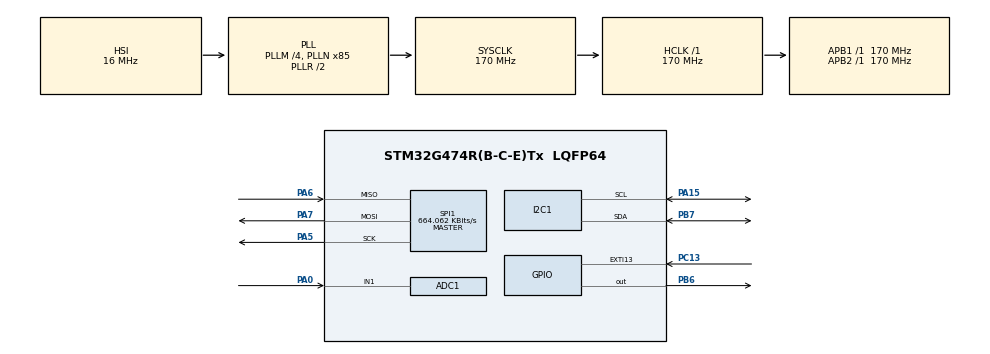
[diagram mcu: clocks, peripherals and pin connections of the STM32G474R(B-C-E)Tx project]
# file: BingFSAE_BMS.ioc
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ADC1.Channel-1\#ChannelRegularConversion=ADC_CHANNEL_1
ADC1.NbrOfConversionFlag=1
ADC1.OffsetNumber-1\#ChannelRegularConversion=ADC_OFFSET_NONE
ADC1.Rank-1\#ChannelRegularConversion=1
ADC1.SamplingTime-1\#ChannelRegularConversion=ADC_SAMPLETIME_2CYCLES_5
ADC1.master=1
I2C1.Timing=0x40B285C2
Mcu.Family=STM32G4
Mcu.Name=STM32G474R(B-C-E)Tx
Mcu.Package=LQFP64
NUCLEO-G474RE.BUTTON=1
NUCLEO-G474RE.LD2=true
NUCLEO-G474RE.VCP=true
NVIC.EXTI15_10_IRQn=true\:0\:0\:false\:false\:true\:true\:true\:true
NVIC.PriorityGroup=NVIC_PRIORITYGROUP_4
PA0.Mode=IN1-Single-Ended
PA0.Signal=ADC1_IN1
PA13.GPIO_Label=T_SWDIO
PA13.Signal=SYS_JTMS-SWDIO
PA14.GPIO_Label=T_SWCLK
PA14.Signal=SYS_JTCK-SWCLK
PA15.Mode=I2C
PA15.Signal=I2C1_SCL
PA2.Signal=LPUART1_TX
PA3.Signal=LPUART1_RX
PA5.Mode=Full_Duplex_Master
PA5.Signal=SPI1_SCK
PA6.Mode=Full_Duplex_Master
PA6.Signal=SPI1_MISO
PA7.Mode=Full_Duplex_Master
PA7.Signal=SPI1_MOSI
PB3.GPIO_Label=T_SWO
PB3.Signal=SYS_JTDO-SWO
PB6.Signal=GPIO_Output
PB7.Mode=I2C
PB7.Signal=I2C1_SDA
PC13.Signal=GPXTI13
PC14-OSC32_IN.GPIO_Label=RCC_OSC32_IN
PC14-OSC32_IN.Signal=RCC_OSC32_IN
PC15-OSC32_OUT.GPIO_Label=RCC_OSC32_OUT
PC15-OSC32_OUT.Signal=RCC_OSC32_OUT
PF0-OSC_IN.GPIO_Label=RCC_OSC_IN
PF0-OSC_IN.Signal=RCC_OSC_IN
PF1-OSC_OUT.GPIO_Label=RCC_OSC_OUT
PF1-OSC_OUT.Signal=RCC_OSC_OUT
ProjectManager.HeapSize=0x200
ProjectManager.StackSize=0x400
ProjectManager.TargetToolchain=STM32CubeIDE
RCC.ADC12Freq_Value=170000000
RCC.ADC345Freq_Value=170000000
RCC.AHBFreq_Value=170000000
RCC.APB1Freq_Value=170000000
RCC.APB1TimFreq_Value=170000000
RCC.APB2Freq_Value=170000000
RCC.APB2TimFreq_Value=170000000
RCC.CortexFreq_Value=170000000
RCC.EXTERNAL_CLOCK_VALUE=12288000
RCC.HCLKFreq_Value=170000000
RCC.HSE_VALUE=24000000
RCC.HSI48_VALUE=48000000
RCC.HSI_VALUE=16000000
RCC.LSE_VALUE=32768
RCC.PLLM=RCC_PLLM_DIV4
RCC.PLLN=85
RCC.RTCClockSelection=RCC_RTCCLKSOURCE_LSE
RCC.SYSCLKFreq_VALUE=170000000
RCC.SYSCLKSource=RCC_SYSCLKSOURCE_PLLCLK
RCC.USBFreq_Value=170000000
RCC.VCOOutputFreq_Value=340000000
SPI1.BaudRatePrescaler=SPI_BAUDRATEPRESCALER_256
SPI1.CalculateBaudRate=664.062 KBits/s
SPI1.Direction=SPI_DIRECTION_2LINES
SPI1.Mode=SPI_MODE_MASTER
SPI1.VirtualType=VM_MASTER
VP_NUCLEO-G474RE_VS_BSP_COMMON.Mode=COMMON
VP_SYS_VS_DBSignals.Mode=DisableDeadBatterySignals
VP_TIM2_VS_ClockSourceITR.Mode=TriggerSource_ITR0
VP_TIM2_VS_ControllerModeClock.Mode=Clock Mode
board=NUCLEO-G474RE

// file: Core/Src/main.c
/* USER CODE BEGIN Header */
/**
  ******************************************************************************
  * @file           : main.c
  * @brief          : Main program body
  ******************************************************************************
  * @attention
  *
  * <h2><center>&copy; Copyright (c) 2020 STMicroelectronics.
  * All rights reserved.</center></h2>
  *
  * This software component is licensed by ST under BSD 3-Clause license,
  * the "License"; You may not use this file except in compliance with the
  * License. You may obtain a copy of the License at:
  *                        opensource.org/licenses/BSD-3-Clause
  *
  ******************************************************************************
  */
/* USER CODE END Header */
#include "main.h"

COM_InitTypeDef BspCOMInit;
ADC_HandleTypeDef hadc1;

I2C_HandleTypeDef hi2c1;

SPI_HandleTypeDef hspi1;

TIM_HandleTypeDef htim2;

void SystemClock_Config(void);
static void MX_GPIO_Init(void);
static void MX_ADC1_Init(void);
static void MX_I2C1_Init(void);
static void MX_SPI1_Init(void);
static void MX_TIM2_Init(void);

int main(void)
{

  /* MCU Configuration--------------------------------------------------------*/

  /* Reset of all peripherals, Initializes the Flash interface and the Systick. */
  HAL_Init();

  /* Configure the system clock */
  SystemClock_Config();

  /* Initialize all configured peripherals */
  MX_GPIO_Init();
  MX_ADC1_Init();
  MX_I2C1_Init();
  MX_SPI1_Init();
  MX_TIM2_Init();
  /* USER CODE BEGIN 2 */
  adbms_main();
  /* USER CODE END 2 */

  /* Initialize led */
  BSP_LED_Init(LED_GREEN);

  /* Initialize USER push-button, will be used to trigger an interrupt each time it's pressed.*/
  BSP_PB_Init(BUTTON_USER, BUTTON_MODE_EXTI);

  /* Initialize COM1 port (115200, 8 bits (7-bit data + 1 stop bit), no parity */
  BspCOMInit.BaudRate   = 115200;
  BspCOMInit.WordLength = COM_WORDLENGTH_8B;
  BspCOMInit.StopBits   = COM_STOPBITS_1;
  BspCOMInit.Parity     = COM_PARITY_NONE;
  BspCOMInit.HwFlowCtl  = COM_HWCONTROL_NONE;
  if (BSP_COM_Init(COM1, &BspCOMInit) != BSP_ERROR_NONE)
  {
    Error_Handler();
  }

  /* Infinite loop */
  while (1)
  {

  }
}

void SystemClock_Config(void)
{
  RCC_OscInitTypeDef RCC_OscInitStruct = {0};
  RCC_ClkInitTypeDef RCC_ClkInitStruct = {0};

  /** Configure the main internal regulator output voltage
  */
  HAL_PWREx_ControlVoltageScaling(PWR_REGULATOR_VOLTAGE_SCALE1_BOOST);

  /** Initializes the RCC Oscillators according to the specified parameters
  * in the RCC_OscInitTypeDef structure.
  */
  RCC_OscInitStruct.OscillatorType = RCC_OSCILLATORTYPE_HSI;
  RCC_OscInitStruct.HSIState = RCC_HSI_ON;
  RCC_OscInitStruct.HSICalibrationValue = RCC_HSICALIBRATION_DEFAULT;
  RCC_OscInitStruct.PLL.PLLState = RCC_PLL_ON;
  RCC_OscInitStruct.PLL.PLLSource = RCC_PLLSOURCE_HSI;
  RCC_OscInitStruct.PLL.PLLM = RCC_PLLM_DIV4;
  RCC_OscInitStruct.PLL.PLLN = 85;
  RCC_OscInitStruct.PLL.PLLP = RCC_PLLP_DIV2;
  RCC_OscInitStruct.PLL.PLLQ = RCC_PLLQ_DIV2;
  RCC_OscInitStruct.PLL.PLLR = RCC_PLLR_DIV2;
  if (HAL_RCC_OscConfig(&RCC_OscInitStruct) != HAL_OK)
  {
    Error_Handler();
  }

  /** Initializes the CPU, AHB and APB buses clocks
  */
  RCC_ClkInitStruct.ClockType = RCC_CLOCKTYPE_HCLK|RCC_CLOCKTYPE_SYSCLK
                              |RCC_CLOCKTYPE_PCLK1|RCC_CLOCKTYPE_PCLK2;
  RCC_ClkInitStruct.SYSCLKSource = RCC_SYSCLKSOURCE_PLLCLK;
  RCC_ClkInitStruct.AHBCLKDivider = RCC_SYSCLK_DIV1;
  RCC_ClkInitStruct.APB1CLKDivider = RCC_HCLK_DIV1;
  RCC_ClkInitStruct.APB2CLKDivider = RCC_HCLK_DIV1;

  if (HAL_RCC_ClockConfig(&RCC_ClkInitStruct, FLASH_LATENCY_4) != HAL_OK)
  {
    Error_Handler();
  }
}

static void MX_ADC1_Init(void)
{

  ADC_MultiModeTypeDef multimode = {0};
  ADC_ChannelConfTypeDef sConfig = {0};

  /** Common config
  */
  hadc1.Instance = ADC1;
  hadc1.Init.ClockPrescaler = ADC_CLOCK_SYNC_PCLK_DIV4;
  hadc1.Init.Resolution = ADC_RESOLUTION_12B;
  hadc1.Init.DataAlign = ADC_DATAALIGN_RIGHT;
  hadc1.Init.GainCompensation = 0;
  hadc1.Init.ScanConvMode = ADC_SCAN_DISABLE;
  hadc1.Init.EOCSelection = ADC_EOC_SINGLE_CONV;
  hadc1.Init.LowPowerAutoWait = DISABLE;
  hadc1.Init.ContinuousConvMode = DISABLE;
  hadc1.Init.NbrOfConversion = 1;
  hadc1.Init.DiscontinuousConvMode = DISABLE;
  hadc1.Init.ExternalTrigConv = ADC_SOFTWARE_START;
  hadc1.Init.ExternalTrigConvEdge = ADC_EXTERNALTRIGCONVEDGE_NONE;
  hadc1.Init.DMAContinuousRequests = DISABLE;
  hadc1.Init.Overrun = ADC_OVR_DATA_PRESERVED;
  hadc1.Init.OversamplingMode = DISABLE;
  if (HAL_ADC_Init(&hadc1) != HAL_OK)
  {
    Error_Handler();
  }

  /** Configure the ADC multi-mode
  */
  multimode.Mode = ADC_MODE_INDEPENDENT;
  if (HAL_ADCEx_MultiModeConfigChannel(&hadc1, &multimode) != HAL_OK)
  {
    Error_Handler();
  }

  /** Configure Regular Channel
  */
  sConfig.Channel = ADC_CHANNEL_1;
  sConfig.Rank = ADC_REGULAR_RANK_1;
  sConfig.SamplingTime = ADC_SAMPLETIME_2CYCLES_5;
  sConfig.SingleDiff = ADC_SINGLE_ENDED;
  sConfig.OffsetNumber = ADC_OFFSET_NONE;
  sConfig.Offset = 0;
  if (HAL_ADC_ConfigChannel(&hadc1, &sConfig) != HAL_OK)
  {
    Error_Handler();
  }

}

static void MX_I2C1_Init(void)
{

  hi2c1.Instance = I2C1;
  hi2c1.Init.Timing = 0x40B285C2;
  hi2c1.Init.OwnAddress1 = 0;
  hi2c1.Init.AddressingMode = I2C_ADDRESSINGMODE_7BIT;
  hi2c1.Init.DualAddressMode = I2C_DUALADDRESS_DISABLE;
  hi2c1.Init.OwnAddress2 = 0;
  hi2c1.Init.OwnAddress2Masks = I2C_OA2_NOMASK;
  hi2c1.Init.GeneralCallMode = I2C_GENERALCALL_DISABLE;
  hi2c1.Init.NoStretchMode = I2C_NOSTRETCH_DISABLE;
  if (HAL_I2C_Init(&hi2c1) != HAL_OK)
  {
    Error_Handler();
  }

  /** Configure Analogue filter
  */
  if (HAL_I2CEx_ConfigAnalogFilter(&hi2c1, I2C_ANALOGFILTER_ENABLE) != HAL_OK)
  {
    Error_Handler();
  }

  /** Configure Digital filter
  */
  if (HAL_I2CEx_ConfigDigitalFilter(&hi2c1, 0) != HAL_OK)
  {
    Error_Handler();
  }

}

static void MX_SPI1_Init(void)
{

  /* SPI1 parameter configuration*/
  hspi1.Instance = SPI1;
  hspi1.Init.Mode = SPI_MODE_MASTER;
  hspi1.Init.Direction = SPI_DIRECTION_2LINES;
  hspi1.Init.DataSize = SPI_DATASIZE_4BIT;
  hspi1.Init.CLKPolarity = SPI_POLARITY_LOW;
  hspi1.Init.CLKPhase = SPI_PHASE_1EDGE;
  hspi1.Init.NSS = SPI_NSS_SOFT;
  hspi1.Init.BaudRatePrescaler = SPI_BAUDRATEPRESCALER_256;
  hspi1.Init.FirstBit = SPI_FIRSTBIT_MSB;
  hspi1.Init.TIMode = SPI_TIMODE_DISABLE;
  hspi1.Init.CRCCalculation = SPI_CRCCALCULATION_DISABLE;
  hspi1.Init.CRCPolynomial = 7;
  hspi1.Init.CRCLength = SPI_CRC_LENGTH_DATASIZE;
  hspi1.Init.NSSPMode = SPI_NSS_PULSE_ENABLE;
  if (HAL_SPI_Init(&hspi1) != HAL_OK)
  {
    Error_Handler();
  }

}

static void MX_TIM2_Init(void)
{

  TIM_SlaveConfigTypeDef sSlaveConfig = {0};
  TIM_MasterConfigTypeDef sMasterConfig = {0};

  htim2.Instance = TIM2;
  htim2.Init.Prescaler = 0;
  htim2.Init.CounterMode = TIM_COUNTERMODE_UP;
  htim2.Init.Period = 4294967295;
  htim2.Init.ClockDivision = TIM_CLOCKDIVISION_DIV1;
  htim2.Init.AutoReloadPreload = TIM_AUTORELOAD_PRELOAD_DISABLE;
  if (HAL_TIM_Base_Init(&htim2) != HAL_OK)
  {
    Error_Handler();
  }
  sSlaveConfig.SlaveMode = TIM_SLAVEMODE_EXTERNAL1;
  sSlaveConfig.InputTrigger = TIM_TS_ITR0;
  if (HAL_TIM_SlaveConfigSynchro(&htim2, &sSlaveConfig) != HAL_OK)
  {
    Error_Handler();
  }
  sMasterConfig.MasterOutputTrigger = TIM_TRGO_RESET;
  sMasterConfig.MasterSlaveMode = TIM_MASTERSLAVEMODE_DISABLE;
  if (HAL_TIMEx_MasterConfigSynchronization(&htim2, &sMasterConfig) != HAL_OK)
  {
    Error_Handler();
  }

}

static void MX_GPIO_Init(void)
{
  GPIO_InitTypeDef GPIO_InitStruct = {0};

  /* GPIO Ports Clock Enable */
  __HAL_RCC_GPIOC_CLK_ENABLE();
  __HAL_RCC_GPIOF_CLK_ENABLE();
  __HAL_RCC_GPIOA_CLK_ENABLE();
  __HAL_RCC_GPIOB_CLK_ENABLE();

  /*Configure GPIO pin Output Level */
  HAL_GPIO_WritePin(GPIOB, GPIO_PIN_6, GPIO_PIN_RESET);

  /*Configure GPIO pin : PB6 */
  GPIO_InitStruct.Pin = GPIO_PIN_6;
  GPIO_InitStruct.Mode = GPIO_MODE_OUTPUT_PP;
  GPIO_InitStruct.Pull = GPIO_NOPULL;
  GPIO_InitStruct.Speed = GPIO_SPEED_FREQ_LOW;
  HAL_GPIO_Init(GPIOB, &GPIO_InitStruct);

}

void Error_Handler(void)
{
}
